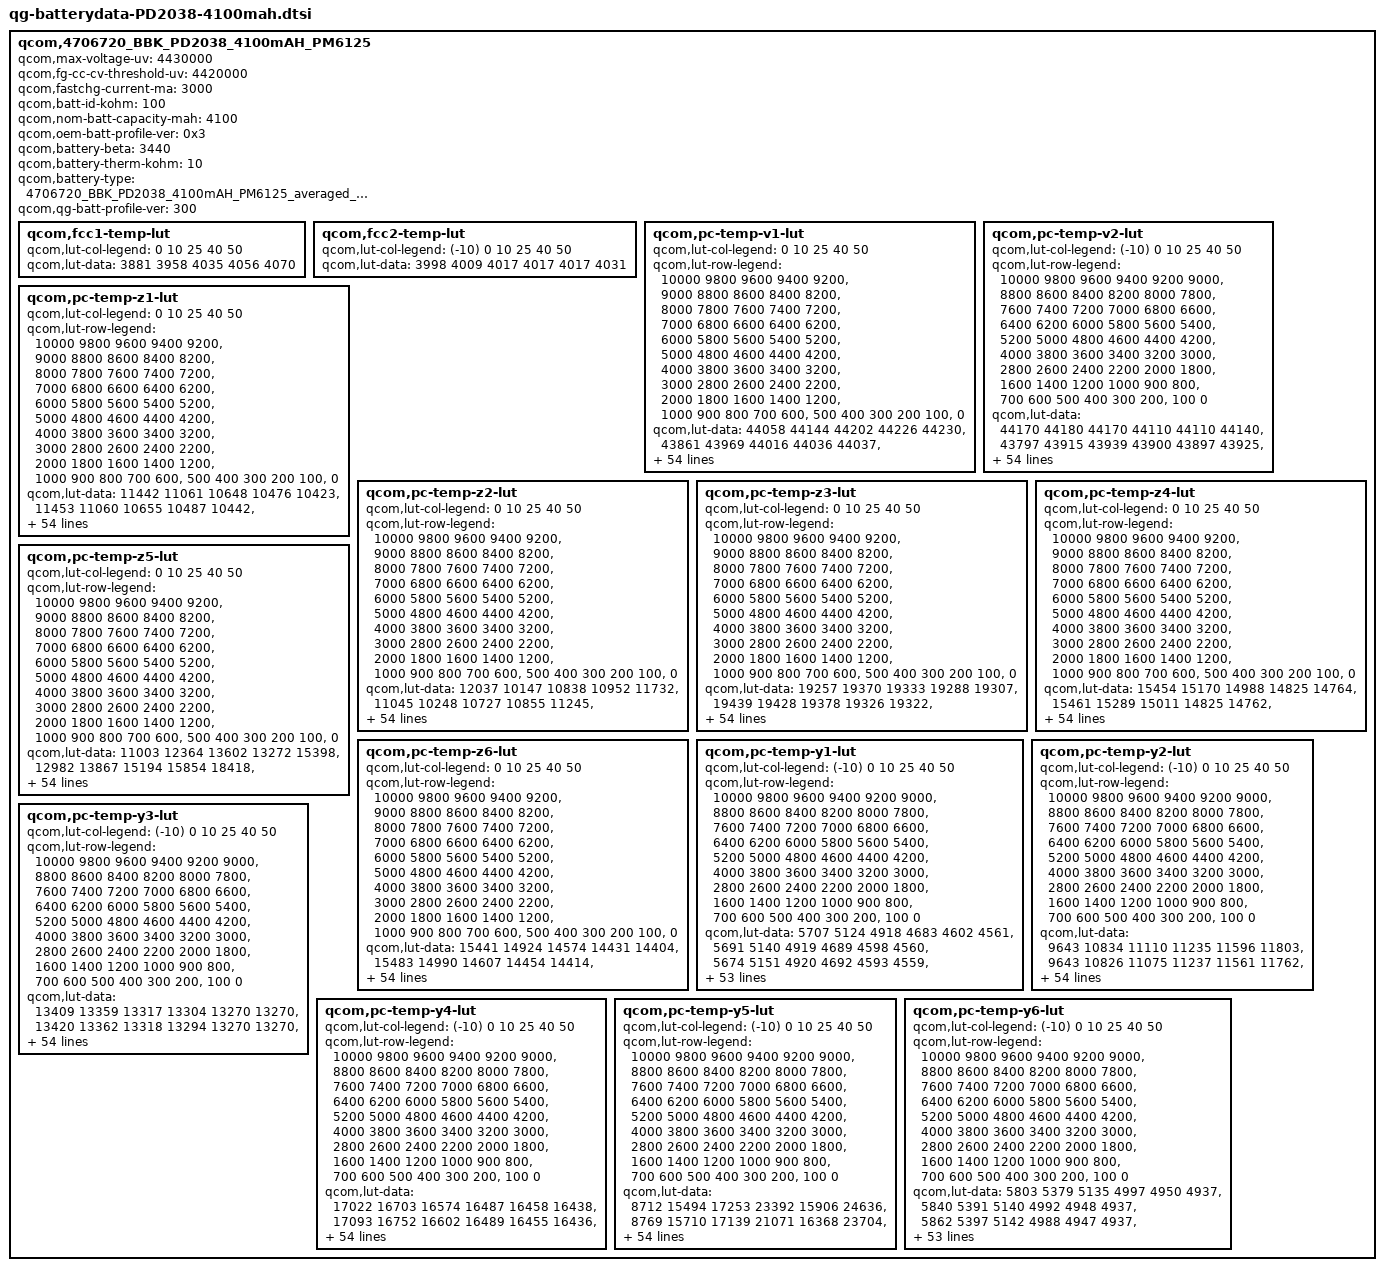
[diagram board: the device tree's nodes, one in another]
qcom,4706720_BBK_PD2038_4100mAH_PM6125 {
    /* 4706720_BBK_PD2038_4100mAH_PM6125_averaged_Master_Jul13th2020 */
    qcom,max-voltage-uv = <4430000>;
    qcom,fg-cc-cv-threshold-uv = <4420000>;
    qcom,fastchg-current-ma = <3000>;
    qcom,batt-id-kohm = <100>;
    qcom,nom-batt-capacity-mah = <4100>;/*min value*/
    qcom,oem-batt-profile-ver = <0x3>;
    qcom,battery-beta = <3440>;
    qcom,battery-therm-kohm = <10>;
    qcom,battery-type = "4706720_BBK_PD2038_4100mAH_PM6125_averaged_Master_Jul13th2020";
    qcom,qg-batt-profile-ver = <300>;

	qcom,fcc1-temp-lut {
		qcom,lut-col-legend = <0 10 25 40 50>;
		qcom,lut-data = <3881 3958 4035 4056 4070>;
	};

	qcom,fcc2-temp-lut {
		qcom,lut-col-legend = <(-10) 0 10 25 40 50>;
		qcom,lut-data = <3998 4009 4017 4017 4017 4031>;
	};

	qcom,pc-temp-v1-lut {
		qcom,lut-col-legend = <0 10 25 40 50>;
		qcom,lut-row-legend = <10000 9800 9600 9400 9200>,
			<9000 8800 8600 8400 8200>,
			<8000 7800 7600 7400 7200>,
			<7000 6800 6600 6400 6200>,
			<6000 5800 5600 5400 5200>,
			<5000 4800 4600 4400 4200>,
			<4000 3800 3600 3400 3200>,
			<3000 2800 2600 2400 2200>,
			<2000 1800 1600 1400 1200>,
			<1000 900 800 700 600>,
			<500 400 300 200 100>,
			<0>;
		qcom,lut-data = <44058 44144 44202 44226 44230>,
			<43861 43969 44016 44036 44037>,
			<43654 43771 43822 43841 43841>,
			<43436 43559 43622 43640 43642>,
			<43206 43339 43412 43434 43441>,
			<42971 43107 43188 43217 43229>,
			<42736 42872 42953 42990 43001>,
			<42499 42633 42714 42756 42767>,
			<42267 42393 42475 42519 42531>,
			<42035 42156 42234 42276 42291>,
			<41807 41923 41996 42038 42054>,
			<41589 41695 41760 41801 41818>,
			<41375 41471 41530 41570 41586>,
			<41171 41253 41306 41342 41359>,
			<40977 41044 41088 41120 41137>,
			<40789 40845 40878 40906 40921>,
			<40600 40653 40673 40699 40712>,
			<40412 40466 40476 40499 40509>,
			<40218 40285 40296 40314 40320>,
			<40004 40090 40118 40135 40140>,
			<39772 39849 39914 39939 39947>,
			<39563 39598 39679 39714 39724>,
			<39387 39397 39455 39492 39501>,
			<39231 39228 39263 39294 39303>,
			<39102 39083 39089 39111 39120>,
			<38992 38961 38943 38956 38962>,
			<38898 38854 38820 38827 38830>,
			<38813 38755 38711 38714 38713>,
			<38737 38662 38610 38607 38603>,
			<38667 38577 38517 38508 38501>,
			<38601 38504 38434 38417 38408>,
			<38538 38438 38358 38332 38323>,
			<38481 38378 38289 38255 38245>,
			<38428 38323 38231 38187 38174>,
			<38378 38273 38180 38128 38111>,
			<38333 38227 38129 38066 38042>,
			<38292 38187 38083 38002 37962>,
			<38235 38138 38032 37932 37876>,
			<38144 38056 37958 37852 37786>,
			<38028 37945 37860 37758 37693>,
			<37904 37825 37749 37653 37588>,
			<37764 37691 37626 37530 37462>,
			<37601 37540 37486 37391 37321>,
			<37418 37364 37315 37227 37158>,
			<37303 37212 37170 37095 37033>,
			<37218 37130 37092 37023 36968>,
			<37185 37106 37069 37007 36950>,
			<37157 37089 37049 36990 36935>,
			<37119 37059 37025 36966 36909>,
			<37011 36965 36930 36849 36739>,
			<36669 36616 36587 36497 36373>,
			<36182 36137 36120 36035 35898>,
			<35564 35523 35517 35441 35285>,
			<34723 34683 34697 34634 34449>,
			<33386 33352 33411 33394 33146>,
			<30000 30000 30000 30000 30000>;
	};

	qcom,pc-temp-v2-lut {
		qcom,lut-col-legend = <(-10) 0 10 25 40 50>;
		qcom,lut-row-legend = <10000 9800 9600 9400 9200 9000>,
			<8800 8600 8400 8200 8000 7800>,
			<7600 7400 7200 7000 6800 6600>,
			<6400 6200 6000 5800 5600 5400>,
			<5200 5000 4800 4600 4400 4200>,
			<4000 3800 3600 3400 3200 3000>,
			<2800 2600 2400 2200 2000 1800>,
			<1600 1400 1200 1000 900 800>,
			<700 600 500 400 300 200>,
			<100 0>;
		qcom,lut-data = <44170 44180 44170 44110 44110 44140>,
			<43797 43915 43939 43900 43897 43925>,
			<43470 43661 43712 43687 43683 43709>,
			<43198 43421 43491 43471 43468 43495>,
			<42979 43196 43277 43254 43254 43283>,
			<42764 42971 43059 43031 43036 43066>,
			<42521 42736 42827 42801 42806 42837>,
			<42270 42498 42588 42566 42570 42601>,
			<42030 42261 42352 42330 42334 42366>,
			<41804 42024 42115 42092 42096 42128>,
			<41585 41791 41881 41856 41861 41892>,
			<41373 41561 41651 41624 41630 41659>,
			<41168 41335 41425 41396 41404 41430>,
			<40966 41120 41203 41172 41181 41206>,
			<40775 40917 40985 40953 40963 40986>,
			<40573 40719 40771 40740 40751 40773>,
			<40315 40516 40564 40536 40549 40567>,
			<39994 40312 40362 40339 40353 40368>,
			<39700 40090 40153 40141 40161 40174>,
			<39462 39825 39931 39941 39974 39990>,
			<39246 39550 39701 39735 39782 39801>,
			<39038 39311 39465 39508 39557 39572>,
			<38836 39094 39217 39255 39294 39309>,
			<38659 38906 39006 39040 39071 39091>,
			<38515 38749 38848 38882 38915 38935>,
			<38393 38611 38713 38749 38784 38804>,
			<38292 38483 38588 38628 38663 38680>,
			<38211 38364 38472 38518 38552 38567>,
			<38139 38254 38365 38417 38450 38462>,
			<38072 38151 38265 38321 38354 38365>,
			<38012 38057 38172 38232 38265 38274>,
			<37954 37985 38086 38149 38184 38191>,
			<37901 37931 38006 38075 38113 38117>,
			<37847 37882 37933 38001 38039 38036>,
			<37788 37833 37870 37925 37950 37937>,
			<37724 37786 37814 37846 37851 37828>,
			<37655 37736 37755 37761 37750 37717>,
			<37578 37690 37695 37666 37643 37602>,
			<37495 37634 37628 37567 37538 37492>,
			<37398 37550 37543 37476 37443 37396>,
			<37287 37426 37438 37388 37354 37306>,
			<37166 37285 37319 37283 37249 37196>,
			<37029 37123 37171 37134 37105 37049>,
			<36895 36966 37030 37007 36979 36927>,
			<36792 36835 36914 36925 36891 36837>,
			<36700 36748 36847 36884 36851 36804>,
			<36654 36716 36819 36866 36836 36786>,
			<36596 36679 36786 36833 36808 36755>,
			<36493 36619 36723 36756 36746 36665>,
			<36262 36463 36565 36515 36540 36407>,
			<35860 36084 36175 36070 36120 35958>,
			<35289 35559 35615 35491 35580 35387>,
			<34507 34862 34913 34726 34868 34628>,
			<33360 33903 33905 33630 33865 33557>,
			<31486 32325 32298 32018 32384 32107>,
			<29018 29007 29005 29349 30157 29005>;
	};

	qcom,pc-temp-z1-lut {
		qcom,lut-col-legend = <0 10 25 40 50>;
		qcom,lut-row-legend = <10000 9800 9600 9400 9200>,
			<9000 8800 8600 8400 8200>,
			<8000 7800 7600 7400 7200>,
			<7000 6800 6600 6400 6200>,
			<6000 5800 5600 5400 5200>,
			<5000 4800 4600 4400 4200>,
			<4000 3800 3600 3400 3200>,
			<3000 2800 2600 2400 2200>,
			<2000 1800 1600 1400 1200>,
			<1000 900 800 700 600>,
			<500 400 300 200 100>,
			<0>;
		qcom,lut-data = <11442 11061 10648 10476 10423>,
			<11453 11060 10655 10487 10442>,
			<11458 11063 10656 10492 10453>,
			<11458 11067 10653 10491 10452>,
			<11451 11066 10650 10487 10450>,
			<11444 11061 10646 10485 10448>,
			<11439 11058 10643 10483 10446>,
			<11435 11060 10641 10481 10444>,
			<11432 11064 10640 10478 10443>,
			<11430 11064 10639 10475 10441>,
			<11429 11062 10636 10474 10441>,
			<11431 11060 10632 10474 10442>,
			<11440 11059 10629 10474 10444>,
			<11446 11058 10629 10474 10444>,
			<11444 11057 10630 10473 10444>,
			<11440 11047 10630 10473 10444>,
			<11434 11037 10633 10476 10445>,
			<11420 11034 10635 10479 10446>,
			<11408 11033 10634 10478 10447>,
			<11408 11033 10631 10476 10448>,
			<11411 11042 10631 10476 10449>,
			<11413 11055 10633 10477 10451>,
			<11414 11057 10636 10480 10453>,
			<11415 11049 10639 10482 10454>,
			<11418 11044 10643 10486 10455>,
			<11426 11049 10647 10490 10456>,
			<11435 11058 10654 10493 10459>,
			<11438 11061 10659 10496 10461>,
			<11440 11055 10662 10498 10464>,
			<11440 11049 10664 10499 10465>,
			<11429 11049 10666 10501 10467>,
			<11415 11050 10666 10502 10469>,
			<11414 11050 10667 10504 10471>,
			<11424 11050 10669 10506 10473>,
			<11433 11050 10673 10509 10475>,
			<11436 11051 10678 10512 10477>,
			<11438 11054 10683 10514 10479>,
			<11439 11059 10686 10516 10480>,
			<11441 11066 10686 10518 10483>,
			<11443 11076 10686 10520 10485>,
			<11439 11077 10686 10522 10487>,
			<11423 11069 10686 10524 10488>,
			<11419 11066 10687 10526 10489>,
			<11423 11069 10694 10526 10492>,
			<11422 11070 10694 10525 10491>,
			<11434 11071 10700 10530 10493>,
			<11448 11073 10702 10525 10491>,
			<11436 11086 10694 10526 10492>,
			<11430 11087 10695 10528 10493>,
			<11445 11089 10698 10533 10497>,
			<11431 11095 10703 10533 10503>,
			<11440 11091 10716 10540 10503>,
			<11452 11117 10725 10544 10512>,
			<11466 11111 10730 10553 10517>,
			<11466 11111 10730 10553 10517>,
			<11466 11111 10730 10553 10517>;
	};

	qcom,pc-temp-z2-lut {
		qcom,lut-col-legend = <0 10 25 40 50>;
		qcom,lut-row-legend = <10000 9800 9600 9400 9200>,
			<9000 8800 8600 8400 8200>,
			<8000 7800 7600 7400 7200>,
			<7000 6800 6600 6400 6200>,
			<6000 5800 5600 5400 5200>,
			<5000 4800 4600 4400 4200>,
			<4000 3800 3600 3400 3200>,
			<3000 2800 2600 2400 2200>,
			<2000 1800 1600 1400 1200>,
			<1000 900 800 700 600>,
			<500 400 300 200 100>,
			<0>;
		qcom,lut-data = <12037 10147 10838 10952 11732>,
			<11045 10248 10727 10855 11245>,
			<10384 10336 10693 10809 10964>,
			<10275 10399 10707 10808 10928>,
			<10263 10415 10722 10808 10913>,
			<10259 10421 10720 10806 10911>,
			<10264 10423 10710 10797 10923>,
			<10275 10422 10698 10791 10942>,
			<10278 10419 10683 10799 10957>,
			<10277 10417 10670 10817 10972>,
			<10276 10414 10666 10833 10988>,
			<10272 10412 10664 10848 11006>,
			<10264 10408 10661 10864 11019>,
			<10260 10405 10637 10884 11000>,
			<10262 10401 10607 10908 10949>,
			<10266 10397 10606 10937 10935>,
			<10271 10392 10621 10983 11040>,
			<10279 10388 10631 11014 11148>,
			<10286 10383 10623 11009 11144>,
			<10277 10382 10608 10991 11105>,
			<10247 10390 10595 10960 11065>,
			<10230 10403 10581 10866 11029>,
			<10242 10406 10574 10789 10990>,
			<10261 10406 10612 10793 10935>,
			<10265 10406 10682 10812 10865>,
			<10259 10396 10700 10818 10840>,
			<10252 10378 10693 10790 10873>,
			<10250 10372 10684 10761 10919>,
			<10248 10382 10669 10771 10943>,
			<10246 10395 10651 10805 10961>,
			<10226 10403 10649 10828 10967>,
			<10202 10409 10691 10835 10956>,
			<10204 10412 10731 10841 10943>,
			<10243 10407 10735 10859 10967>,
			<10278 10400 10735 10894 11068>,
			<10286 10396 10739 10933 11147>,
			<10290 10393 10778 10985 11179>,
			<10296 10392 10834 11030 11205>,
			<10306 10426 10880 11039 11246>,
			<10314 10487 10926 11043 11304>,
			<10315 10504 10941 11044 11331>,
			<10309 10491 10877 11040 11283>,
			<10298 10484 10833 11031 11220>,
			<10284 10481 10847 11009 11181>,
			<10768 10504 10814 11036 11233>,
			<15094 10479 10899 11076 11158>,
			<14915 10478 10867 11113 11118>,
			<14921 10458 10785 11116 11159>,
			<14655 10450 10805 11094 11275>,
			<14225 10507 10896 10932 10895>,
			<14290 10506 10836 10685 10787>,
			<15438 10540 10807 10695 10696>,
			<12299 10555 10667 10601 10677>,
			<11020 10448 10545 10593 10711>,
			<11020 10448 10545 10593 10711>,
			<11020 10448 10545 10593 10711>;
	};

	qcom,pc-temp-z3-lut {
		qcom,lut-col-legend = <0 10 25 40 50>;
		qcom,lut-row-legend = <10000 9800 9600 9400 9200>,
			<9000 8800 8600 8400 8200>,
			<8000 7800 7600 7400 7200>,
			<7000 6800 6600 6400 6200>,
			<6000 5800 5600 5400 5200>,
			<5000 4800 4600 4400 4200>,
			<4000 3800 3600 3400 3200>,
			<3000 2800 2600 2400 2200>,
			<2000 1800 1600 1400 1200>,
			<1000 900 800 700 600>,
			<500 400 300 200 100>,
			<0>;
		qcom,lut-data = <19257 19370 19333 19288 19307>,
			<19439 19428 19378 19326 19322>,
			<19569 19484 19392 19344 19329>,
			<19622 19524 19392 19344 19326>,
			<19653 19527 19392 19343 19318>,
			<19666 19524 19391 19340 19316>,
			<19660 19520 19389 19333 19317>,
			<19648 19517 19387 19328 19319>,
			<19641 19513 19382 19329 19318>,
			<19640 19509 19376 19330 19316>,
			<19639 19505 19373 19330 19315>,
			<19636 19501 19372 19328 19314>,
			<19628 19499 19369 19326 19314>,
			<19621 19497 19360 19324 19310>,
			<19618 19495 19350 19321 19304>,
			<19615 19493 19349 19318 19302>,
			<19615 19491 19350 19313 19303>,
			<19618 19491 19350 19310 19304>,
			<19624 19492 19351 19310 19304>,
			<19633 19493 19352 19310 19303>,
			<19647 19495 19355 19311 19303>,
			<19655 19501 19361 19315 19310>,
			<19653 19510 19370 19321 19318>,
			<19650 19530 19384 19326 19321>,
			<19650 19544 19400 19330 19322>,
			<19654 19541 19403 19332 19322>,
			<19658 19532 19403 19331 19322>,
			<19653 19525 19401 19331 19321>,
			<19638 19520 19398 19330 19321>,
			<19625 19514 19393 19328 19320>,
			<19616 19507 19389 19326 19318>,
			<19608 19499 19386 19325 19312>,
			<19603 19492 19383 19324 19306>,
			<19598 19487 19379 19323 19303>,
			<19595 19483 19376 19321 19301>,
			<19594 19481 19373 19319 19300>,
			<19593 19481 19371 19317 19302>,
			<19592 19480 19368 19315 19305>,
			<19584 19475 19366 19314 19305>,
			<19573 19465 19362 19315 19303>,
			<19568 19460 19359 19316 19302>,
			<19566 19459 19356 19321 19304>,
			<19563 19456 19354 19325 19307>,
			<19554 19445 19354 19324 19310>,
			<19286 19436 19352 19322 19309>,
			<19257 19431 19342 19319 19301>,
			<19257 19427 19343 19307 19303>,
			<19257 19414 19342 19309 19299>,
			<19257 19412 19337 19309 19298>,
			<19257 19381 19345 19321 19319>,
			<19257 19364 19331 19329 19318>,
			<19257 19369 19334 19332 19319>,
			<19257 19333 19344 19329 19322>,
			<19258 19353 19345 19334 19323>,
			<19258 19353 19345 19334 19323>,
			<19258 19353 19345 19334 19323>;
	};

	qcom,pc-temp-z4-lut {
		qcom,lut-col-legend = <0 10 25 40 50>;
		qcom,lut-row-legend = <10000 9800 9600 9400 9200>,
			<9000 8800 8600 8400 8200>,
			<8000 7800 7600 7400 7200>,
			<7000 6800 6600 6400 6200>,
			<6000 5800 5600 5400 5200>,
			<5000 4800 4600 4400 4200>,
			<4000 3800 3600 3400 3200>,
			<3000 2800 2600 2400 2200>,
			<2000 1800 1600 1400 1200>,
			<1000 900 800 700 600>,
			<500 400 300 200 100>,
			<0>;
		qcom,lut-data = <15454 15170 14988 14825 14764>,
			<15461 15289 15011 14825 14762>,
			<15462 15247 15011 14825 14759>,
			<15438 15179 14960 14813 14755>,
			<15307 15118 14899 14790 14749>,
			<15182 15053 14876 14777 14743>,
			<15131 15007 14863 14769 14736>,
			<15095 14984 14850 14762 14728>,
			<15071 14967 14838 14754 14722>,
			<15054 14951 14826 14745 14716>,
			<15040 14935 14813 14737 14710>,
			<15030 14921 14801 14729 14703>,
			<15021 14908 14790 14722 14697>,
			<15012 14896 14783 14714 14692>,
			<14999 14889 14776 14707 14689>,
			<14986 14885 14767 14700 14683>,
			<14986 14882 14756 14693 14673>,
			<15019 14882 14747 14686 14663>,
			<15071 14883 14742 14681 14659>,
			<15128 14885 14739 14677 14656>,
			<15200 14982 14752 14680 14656>,
			<15241 15121 14837 14718 14679>,
			<15251 15144 14898 14760 14709>,
			<15257 15104 14895 14774 14724>,
			<15253 15061 14886 14782 14734>,
			<15212 15033 14876 14784 14737>,
			<15166 15010 14857 14775 14732>,
			<15145 14996 14840 14763 14725>,
			<15130 14989 14828 14752 14717>,
			<15124 14984 14820 14742 14709>,
			<15123 14978 14813 14732 14702>,
			<15122 14974 14807 14723 14696>,
			<15120 14971 14803 14715 14691>,
			<15115 14969 14800 14710 14687>,
			<15109 14968 14798 14707 14682>,
			<15102 14965 14798 14706 14680>,
			<15094 14960 14811 14725 14694>,
			<15086 14955 14824 14748 14711>,
			<15077 14951 14825 14749 14712>,
			<15066 14947 14824 14741 14704>,
			<15044 14937 14822 14731 14696>,
			<15001 14904 14804 14717 14688>,
			<14962 14873 14785 14709 14683>,
			<14931 14851 14778 14707 14681>,
			<15065 14816 14770 14707 14682>,
			<15056 14775 14753 14704 14683>,
			<15042 14754 14728 14695 14669>,
			<15026 14736 14704 14673 14655>,
			<15022 14729 14693 14662 14647>,
			<15026 14768 14700 14659 14642>,
			<15037 14796 14715 14654 14641>,
			<15037 14785 14708 14649 14642>,
			<15037 14822 14697 14652 14640>,
			<15042 14801 14696 14648 14641>,
			<15042 14801 14696 14648 14641>,
			<15042 14801 14696 14648 14641>;
	};

	qcom,pc-temp-z5-lut {
		qcom,lut-col-legend = <0 10 25 40 50>;
		qcom,lut-row-legend = <10000 9800 9600 9400 9200>,
			<9000 8800 8600 8400 8200>,
			<8000 7800 7600 7400 7200>,
			<7000 6800 6600 6400 6200>,
			<6000 5800 5600 5400 5200>,
			<5000 4800 4600 4400 4200>,
			<4000 3800 3600 3400 3200>,
			<3000 2800 2600 2400 2200>,
			<2000 1800 1600 1400 1200>,
			<1000 900 800 700 600>,
			<500 400 300 200 100>,
			<0>;
		qcom,lut-data = <11003 12364 13602 13272 15398>,
			<12982 13867 15194 15854 18418>,
			<14697 15269 16092 17413 19950>,
			<16129 16452 16549 18058 19540>,
			<17422 17214 16838 18446 18534>,
			<18332 17789 17017 18392 18241>,
			<18780 18145 17150 17711 18693>,
			<19085 18318 17189 17224 19177>,
			<19421 18437 17067 17530 19323>,
			<19899 18558 16922 18108 19406>,
			<20267 18667 16968 18340 19509>,
			<20302 18798 17190 18424 19675>,
			<20272 19016 17303 18461 19794>,
			<20254 19323 16796 18458 19395>,
			<20410 19647 16117 18446 18337>,
			<20687 20066 16074 18372 17966>,
			<20761 20385 16434 17870 18723>,
			<20623 20377 16892 17444 19683>,
			<20484 20202 17527 17707 20186>,
			<20807 19952 18157 18312 20567>,
			<21899 19416 18017 18370 20611>,
			<22513 18785 16489 16725 18850>,
			<21364 18528 15387 15192 16811>,
			<19599 18402 15549 15121 16360>,
			<19297 18345 15976 15135 16168>,
			<20453 18650 16479 15176 16124>,
			<21602 19441 17184 15541 16499>,
			<21907 20273 17934 16078 17116>,
			<22078 21317 18556 16545 17737>,
			<22153 22173 19152 17035 18454>,
			<22172 22446 19894 17630 18739>,
			<22187 22595 20934 18422 18457>,
			<22228 22687 21947 19323 18113>,
			<22344 22739 22743 20352 18321>,
			<22497 22784 23433 21522 19251>,
			<22706 22890 23624 21939 19736>,
			<22957 23115 23184 20461 19450>,
			<23043 23255 22437 18674 18982>,
			<22913 22869 21483 18426 18638>,
			<22715 22127 20183 18402 18321>,
			<22586 21807 19414 18414 18191>,
			<22492 21741 19183 19667 18831>,
			<22310 21469 18943 20638 19441>,
			<21785 19975 18486 19866 19530>,
			<12696 20505 18198 18851 19092>,
			<11295 20788 17505 18648 17427>,
			<11222 20915 19092 17510 19498>,
			<11119 19131 21063 20205 21396>,
			<11104 19090 21431 22638 22854>,
			<11116 15310 18895 20722 29444>,
			<11109 13832 15254 23449 28009>,
			<11073 13877 15358 24963 29176>,
			<11018 12472 16171 22772 31523>,
			<10956 12950 15863 24829 31491>,
			<10956 12950 15863 24829 31491>,
			<10956 12950 15863 24829 31491>;
	};

	qcom,pc-temp-z6-lut {
		qcom,lut-col-legend = <0 10 25 40 50>;
		qcom,lut-row-legend = <10000 9800 9600 9400 9200>,
			<9000 8800 8600 8400 8200>,
			<8000 7800 7600 7400 7200>,
			<7000 6800 6600 6400 6200>,
			<6000 5800 5600 5400 5200>,
			<5000 4800 4600 4400 4200>,
			<4000 3800 3600 3400 3200>,
			<3000 2800 2600 2400 2200>,
			<2000 1800 1600 1400 1200>,
			<1000 900 800 700 600>,
			<500 400 300 200 100>,
			<0>;
		qcom,lut-data = <15441 14924 14574 14431 14404>,
			<15483 14990 14607 14454 14414>,
			<15493 14979 14615 14464 14418>,
			<15478 14959 14591 14459 14416>,
			<15391 14932 14562 14447 14409>,
			<15304 14891 14549 14439 14404>,
			<15258 14858 14541 14431 14400>,
			<15222 14839 14533 14425 14398>,
			<15197 14824 14524 14421 14394>,
			<15179 14810 14514 14418 14391>,
			<15166 14797 14507 14414 14388>,
			<15152 14786 14500 14409 14385>,
			<15139 14776 14493 14405 14381>,
			<15127 14767 14485 14400 14377>,
			<15115 14761 14477 14396 14373>,
			<15104 14757 14471 14391 14369>,
			<15102 14753 14467 14386 14365>,
			<15116 14753 14464 14381 14362>,
			<15137 14753 14463 14379 14360>,
			<15166 14754 14463 14377 14358>,
			<15207 14800 14469 14379 14358>,
			<15231 14865 14509 14399 14373>,
			<15237 14878 14542 14421 14392>,
			<15241 14873 14550 14431 14400>,
			<15240 14865 14554 14437 14405>,
			<15227 14855 14554 14439 14407>,
			<15211 14841 14547 14435 14405>,
			<15199 14833 14539 14429 14401>,
			<15189 14829 14533 14424 14398>,
			<15182 14826 14527 14419 14394>,
			<15179 14822 14523 14414 14390>,
			<15177 14818 14520 14410 14384>,
			<15177 14816 14517 14406 14379>,
			<15177 14815 14515 14403 14376>,
			<15178 14815 14513 14401 14373>,
			<15180 14815 14512 14401 14372>,
			<15185 14817 14518 14408 14379>,
			<15186 14819 14523 14417 14388>,
			<15186 14818 14523 14417 14389>,
			<15186 14817 14522 14414 14385>,
			<15184 14815 14520 14411 14381>,
			<15175 14806 14512 14408 14379>,
			<15172 14797 14504 14407 14378>,
			<15172 14790 14502 14406 14380>,
			<15119 14778 14498 14405 14380>,
			<15108 14764 14487 14402 14376>,
			<15110 14755 14478 14392 14371>,
			<15110 14744 14467 14384 14363>,
			<15116 14744 14461 14379 14359>,
			<15130 14752 14470 14385 14369>,
			<15147 14762 14471 14388 14369>,
			<15161 14767 14472 14389 14372>,
			<15179 14774 14475 14390 14374>,
			<15207 14788 14479 14394 14377>,
			<15207 14788 14479 14394 14377>,
			<15207 14788 14479 14394 14377>;
	};

	qcom,pc-temp-y1-lut {
		qcom,lut-col-legend = <(-10) 0 10 25 40 50>;
		qcom,lut-row-legend = <10000 9800 9600 9400 9200 9000>,
			<8800 8600 8400 8200 8000 7800>,
			<7600 7400 7200 7000 6800 6600>,
			<6400 6200 6000 5800 5600 5400>,
			<5200 5000 4800 4600 4400 4200>,
			<4000 3800 3600 3400 3200 3000>,
			<2800 2600 2400 2200 2000 1800>,
			<1600 1400 1200 1000 900 800>,
			<700 600 500 400 300 200>,
			<100 0>;
		qcom,lut-data = <5707 5124 4918 4683 4602 4561>,
			<5691 5140 4919 4689 4598 4560>,
			<5674 5151 4920 4692 4593 4559>,
			<5658 5156 4920 4692 4589 4558>,
			<5644 5158 4920 4690 4585 4558>,
			<5634 5159 4920 4687 4582 4557>,
			<5626 5154 4919 4682 4581 4557>,
			<5621 5143 4916 4675 4580 4557>,
			<5620 5136 4914 4672 4578 4557>,
			<5620 5134 4911 4672 4573 4557>,
			<5621 5131 4909 4672 4569 4556>,
			<5620 5128 4907 4671 4570 4556>,
			<5616 5125 4904 4669 4572 4556>,
			<5615 5123 4902 4667 4574 4556>,
			<5615 5121 4901 4665 4575 4555>,
			<5615 5119 4900 4664 4576 4555>,
			<5615 5119 4899 4663 4576 4555>,
			<5614 5119 4898 4663 4576 4556>,
			<5614 5119 4898 4663 4576 4556>,
			<5611 5117 4898 4665 4577 4558>,
			<5609 5115 4899 4666 4578 4559>,
			<5611 5116 4900 4667 4579 4559>,
			<5623 5122 4903 4667 4579 4559>,
			<5631 5126 4905 4667 4579 4558>,
			<5623 5121 4902 4668 4580 4559>,
			<5607 5112 4898 4669 4581 4560>,
			<5604 5110 4898 4670 4582 4561>,
			<5614 5112 4903 4672 4582 4563>,
			<5623 5114 4908 4674 4582 4565>,
			<5616 5118 4909 4677 4584 4565>,
			<5597 5125 4911 4681 4586 4565>,
			<5587 5127 4911 4683 4588 4566>,
			<5584 5127 4909 4685 4589 4568>,
			<5583 5126 4908 4686 4590 4570>,
			<5581 5123 4908 4687 4592 4570>,
			<5579 5115 4909 4688 4594 4571>,
			<5577 5110 4910 4689 4596 4572>,
			<5576 5109 4910 4692 4597 4574>,
			<5575 5108 4910 4694 4597 4576>,
			<5574 5108 4913 4694 4599 4577>,
			<5572 5108 4919 4694 4600 4578>,
			<5571 5109 4923 4695 4601 4579>,
			<5572 5115 4924 4696 4603 4581>,
			<5573 5121 4924 4699 4603 4582>,
			<5578 5124 4919 4702 4602 4582>,
			<5595 5116 4919 4701 4605 4583>,
			<5612 5108 4920 4700 4607 4582>,
			<5619 5109 4930 4704 4607 4581>,
			<5625 5112 4931 4702 4605 4583>,
			<5611 5126 4923 4706 4607 4586>,
			<5629 5130 4934 4710 4609 4588>,
			<5668 5123 4930 4713 4611 4591>,
			<5684 5132 4948 4714 4619 4595>,
			<5767 5178 4958 4730 4624 4601>,
			<5767 5178 4958 4730 4624 4601>,
			<5767 5178 4958 4730 4624 4601>;
	};

	qcom,pc-temp-y2-lut {
		qcom,lut-col-legend = <(-10) 0 10 25 40 50>;
		qcom,lut-row-legend = <10000 9800 9600 9400 9200 9000>,
			<8800 8600 8400 8200 8000 7800>,
			<7600 7400 7200 7000 6800 6600>,
			<6400 6200 6000 5800 5600 5400>,
			<5200 5000 4800 4600 4400 4200>,
			<4000 3800 3600 3400 3200 3000>,
			<2800 2600 2400 2200 2000 1800>,
			<1600 1400 1200 1000 900 800>,
			<700 600 500 400 300 200>,
			<100 0>;
		qcom,lut-data = <9643 10834 11110 11235 11596 11803>,
			<9643 10826 11075 11237 11561 11762>,
			<9643 10818 11040 11238 11524 11723>,
			<9936 10810 11006 11238 11488 11686>,
			<10329 10800 10978 11237 11457 11652>,
			<10530 10790 10956 11236 11435 11619>,
			<10550 10778 10939 11187 11425 11593>,
			<10559 10765 10927 11095 11418 11567>,
			<10564 10761 10924 11070 11400 11524>,
			<10565 10765 10929 11100 11344 11432>,
			<10568 10771 10937 11126 11298 11366>,
			<10599 10779 10945 11128 11304 11412>,
			<10677 10789 10955 11128 11329 11518>,
			<10709 10807 10967 11128 11354 11548>,
			<10662 10866 10982 11138 11382 11467>,
			<10608 10923 11003 11157 11403 11389>,
			<10612 10925 11047 11190 11382 11407>,
			<10653 10915 11120 11252 11312 11475>,
			<10677 10908 11152 11323 11282 11519>,
			<10680 10907 11130 11427 11394 11534>,
			<10681 10907 11101 11517 11557 11548>,
			<10599 10911 11095 11515 11639 11610>,
			<10148 10929 11093 11460 11695 11750>,
			<9803 10947 11093 11428 11725 11819>,
			<9763 10957 11110 11462 11735 11822>,
			<9742 10965 11140 11513 11741 11824>,
			<9726 10976 11164 11518 11751 11847>,
			<9712 10988 11188 11491 11764 11929>,
			<9701 11009 11200 11472 11783 11992>,
			<9695 11151 11198 11493 11858 12009>,
			<9690 11399 11193 11540 11965 12022>,
			<9686 11440 11181 11576 11980 12053>,
			<9680 11060 11139 11609 11882 12124>,
			<9675 10641 11102 11628 11799 12179>,
			<9672 10477 11092 11597 11843 12199>,
			<9669 10367 11086 11527 11944 12212>,
			<9667 10341 11085 11506 11973 12201>,
			<9665 10475 11092 11555 11897 12100>,
			<9663 10623 11099 11605 11822 12020>,
			<9662 10541 11081 11612 11818 12041>,
			<9660 10188 11020 11614 11819 12088>,
			<9659 9914 10951 11615 11820 12086>,
			<9658 9782 10878 11616 11818 11926>,
			<9658 9710 10792 11611 11811 11838>,
			<9657 9687 10686 11436 11737 11820>,
			<9656 9678 10574 11429 11686 11822>,
			<9656 9675 10551 11445 11655 11676>,
			<9655 9671 10569 11441 11584 11486>,
			<9654 9667 10507 11375 11546 11451>,
			<9654 9664 10454 11202 11362 11403>,
			<9653 9660 10321 11192 11301 11319>,
			<9651 9658 9934 11072 11178 11269>,
			<9649 9655 9814 11001 11188 11263>,
			<9654 9651 9708 10901 11138 11215>,
			<9654 9651 9708 10901 11138 11215>,
			<9654 9651 9708 10901 11138 11215>;
	};

	qcom,pc-temp-y3-lut {
		qcom,lut-col-legend = <(-10) 0 10 25 40 50>;
		qcom,lut-row-legend = <10000 9800 9600 9400 9200 9000>,
			<8800 8600 8400 8200 8000 7800>,
			<7600 7400 7200 7000 6800 6600>,
			<6400 6200 6000 5800 5600 5400>,
			<5200 5000 4800 4600 4400 4200>,
			<4000 3800 3600 3400 3200 3000>,
			<2800 2600 2400 2200 2000 1800>,
			<1600 1400 1200 1000 900 800>,
			<700 600 500 400 300 200>,
			<100 0>;
		qcom,lut-data = <13409 13359 13317 13304 13270 13270>,
			<13420 13362 13318 13294 13270 13270>,
			<13438 13365 13319 13288 13271 13270>,
			<13458 13368 13321 13283 13271 13270>,
			<13474 13370 13322 13280 13272 13270>,
			<13483 13372 13323 13279 13272 13271>,
			<13485 13373 13323 13281 13273 13271>,
			<13486 13374 13323 13285 13274 13272>,
			<13487 13375 13323 13286 13275 13272>,
			<13490 13377 13324 13286 13275 13273>,
			<13492 13379 13326 13286 13275 13273>,
			<13487 13379 13328 13287 13275 13274>,
			<13473 13379 13330 13287 13275 13274>,
			<13459 13379 13331 13287 13275 13274>,
			<13450 13378 13331 13287 13275 13273>,
			<13441 13375 13330 13287 13275 13273>,
			<13433 13371 13328 13287 13275 13272>,
			<13425 13365 13326 13290 13277 13271>,
			<13417 13358 13324 13293 13279 13271>,
			<13411 13351 13321 13294 13282 13274>,
			<13405 13344 13318 13295 13284 13278>,
			<13394 13339 13314 13294 13283 13277>,
			<13377 13334 13309 13287 13275 13272>,
			<13356 13331 13307 13283 13270 13270>,
			<13325 13329 13306 13280 13270 13270>,
			<13292 13328 13306 13279 13270 13270>,
			<13284 13327 13306 13279 13270 13269>,
			<13293 13324 13306 13280 13270 13269>,
			<13305 13321 13305 13281 13270 13268>,
			<13313 13301 13305 13280 13270 13269>,
			<13320 13269 13304 13280 13270 13269>,
			<13332 13259 13303 13280 13270 13269>,
			<13360 13259 13301 13280 13271 13268>,
			<13394 13259 13300 13281 13272 13267>,
			<13423 13260 13300 13281 13271 13267>,
			<13450 13260 13301 13280 13270 13267>,
			<13483 13262 13301 13279 13270 13267>,
			<13525 13295 13303 13279 13270 13267>,
			<13577 13332 13304 13278 13270 13267>,
			<13637 13339 13304 13277 13270 13267>,
			<13709 13341 13304 13277 13271 13268>,
			<13793 13343 13303 13276 13271 13268>,
			<13887 13352 13308 13275 13271 13269>,
			<14004 13367 13314 13275 13270 13269>,
			<14164 13397 13321 13277 13271 13269>,
			<14368 13442 13329 13281 13272 13270>,
			<14488 13470 13332 13283 13273 13272>,
			<14601 13492 13335 13285 13274 13273>,
			<14780 13558 13345 13287 13276 13274>,
			<15034 13635 13358 13288 13278 13274>,
			<15423 13727 13364 13291 13278 13274>,
			<16613 13942 13376 13291 13278 13273>,
			<19581 14338 13427 13294 13277 13273>,
			<25299 15696 13549 13302 13278 13275>,
			<25299 15696 13549 13302 13278 13275>,
			<25299 15696 13549 13302 13278 13275>;
	};

	qcom,pc-temp-y4-lut {
		qcom,lut-col-legend = <(-10) 0 10 25 40 50>;
		qcom,lut-row-legend = <10000 9800 9600 9400 9200 9000>,
			<8800 8600 8400 8200 8000 7800>,
			<7600 7400 7200 7000 6800 6600>,
			<6400 6200 6000 5800 5600 5400>,
			<5200 5000 4800 4600 4400 4200>,
			<4000 3800 3600 3400 3200 3000>,
			<2800 2600 2400 2200 2000 1800>,
			<1600 1400 1200 1000 900 800>,
			<700 600 500 400 300 200>,
			<100 0>;
		qcom,lut-data = <17022 16703 16574 16487 16458 16438>,
			<17093 16752 16602 16489 16455 16436>,
			<17152 16803 16624 16491 16452 16436>,
			<17198 16850 16638 16494 16449 16435>,
			<17227 16884 16646 16496 16448 16435>,
			<17239 16900 16649 16497 16447 16435>,
			<17226 16894 16644 16497 16447 16435>,
			<17199 16880 16633 16497 16449 16436>,
			<17191 16867 16628 16498 16450 16437>,
			<17203 16854 16627 16503 16451 16438>,
			<17225 16845 16626 16509 16454 16441>,
			<17275 16848 16629 16516 16458 16444>,
			<17372 16860 16638 16524 16466 16448>,
			<17454 16880 16649 16533 16474 16453>,
			<17524 16941 16666 16544 16481 16459>,
			<17572 17016 16690 16557 16490 16467>,
			<17513 17068 16735 16572 16498 16475>,
			<17260 17113 16807 16591 16507 16484>,
			<17055 17129 16837 16611 16519 16494>,
			<16960 17032 16827 16637 16542 16510>,
			<16892 16876 16805 16658 16563 16523>,
			<16851 16776 16754 16639 16552 16512>,
			<16820 16698 16637 16552 16498 16471>,
			<16805 16648 16564 16495 16464 16448>,
			<16813 16625 16550 16487 16459 16445>,
			<16828 16609 16542 16483 16457 16444>,
			<16831 16595 16541 16483 16457 16445>,
			<16820 16582 16541 16489 16460 16448>,
			<16811 16574 16541 16497 16464 16452>,
			<16812 16593 16542 16505 16469 16456>,
			<16817 16636 16545 16516 16477 16462>,
			<16818 16660 16547 16526 16486 16469>,
			<16813 16669 16550 16537 16498 16480>,
			<16807 16678 16552 16544 16507 16486>,
			<16809 16697 16550 16542 16501 16477>,
			<16820 16723 16546 16534 16485 16461>,
			<16830 16732 16543 16522 16473 16455>,
			<16837 16711 16541 16495 16465 16453>,
			<16844 16688 16539 16472 16460 16451>,
			<16852 16686 16542 16471 16457 16450>,
			<16860 16687 16552 16474 16454 16448>,
			<16866 16689 16566 16477 16452 16446>,
			<16868 16704 16585 16480 16450 16440>,
			<16869 16725 16609 16482 16449 16439>,
			<16902 16747 16633 16483 16449 16439>,
			<16993 16794 16687 16503 16458 16444>,
			<17065 16829 16704 16516 16462 16445>,
			<17086 16851 16706 16518 16462 16448>,
			<17139 16911 16754 16522 16460 16444>,
			<17179 16958 16779 16502 16443 16435>,
			<17204 16966 16773 16503 16443 16438>,
			<17565 17035 16818 16524 16454 16451>,
			<19520 17214 16922 16567 16470 16468>,
			<32934 18176 17087 16687 16519 16576>,
			<32934 18176 17087 16687 16519 16576>,
			<32934 18176 17087 16687 16519 16576>;
	};

	qcom,pc-temp-y5-lut {
		qcom,lut-col-legend = <(-10) 0 10 25 40 50>;
		qcom,lut-row-legend = <10000 9800 9600 9400 9200 9000>,
			<8800 8600 8400 8200 8000 7800>,
			<7600 7400 7200 7000 6800 6600>,
			<6400 6200 6000 5800 5600 5400>,
			<5200 5000 4800 4600 4400 4200>,
			<4000 3800 3600 3400 3200 3000>,
			<2800 2600 2400 2200 2000 1800>,
			<1600 1400 1200 1000 900 800>,
			<700 600 500 400 300 200>,
			<100 0>;
		qcom,lut-data = <8712 15494 17253 23392 15906 24636>,
			<8769 15710 17139 21071 16368 23704>,
			<10566 15871 16985 18510 16689 22501>,
			<12702 15981 16796 16122 16891 21259>,
			<14546 16046 16576 14325 16998 20212>,
			<15466 16069 16329 13535 17032 19591>,
			<15519 16042 16017 13899 16970 19391>,
			<15541 15968 15681 14624 16808 19269>,
			<15548 15884 15483 14811 16624 19057>,
			<15551 15780 15374 14514 16404 18684>,
			<15552 15636 15290 14126 16107 18209>,
			<15177 15385 15221 13840 15591 17629>,
			<14165 14986 15165 13572 14836 16920>,
			<13764 14555 15035 13311 14240 16204>,
			<14823 13980 14428 13002 13740 15451>,
			<16057 13537 13805 12785 13420 14749>,
			<16179 13795 13667 12816 13452 14130>,
			<16075 14873 13606 13021 13682 13565>,
			<16018 15756 13614 13343 14020 13409>,
			<16218 16294 14751 14237 14879 14150>,
			<16506 16660 16285 15434 15747 15290>,
			<16162 16700 16782 16394 15859 16220>,
			<13899 16664 16965 17323 15853 17130>,
			<11921 16642 17196 17734 15850 17921>,
			<11232 16784 17791 17230 16089 18705>,
			<10779 17015 18432 16486 16440 19278>,
			<10692 17022 18561 16407 16488 19011>,
			<10743 16629 18571 16776 16345 17604>,
			<10787 15970 18574 17038 16151 16683>,
			<10780 14239 18492 16802 15876 16588>,
			<10758 11684 18309 16377 15575 16526>,
			<10766 10937 18146 16333 15529 16302>,
			<11073 11073 17973 16900 15767 15667>,
			<11443 11210 17868 17394 16080 15258>,
			<11567 11235 17994 17432 16336 15773>,
			<11630 11244 18280 17443 16595 16674>,
			<11694 11373 18379 17488 16864 16923>,
			<11790 13730 18375 17783 17202 16937>,
			<11870 16330 18368 18061 17437 16954>,
			<11873 16301 17795 17722 17419 17066>,
			<11827 15147 16220 16608 17301 17328>,
			<11756 13967 15513 15699 17144 17698>,
			<11605 12798 15494 15049 16841 18397>,
			<11439 12189 15497 14814 16709 18642>,
			<11367 12213 15758 15637 17526 18496>,
			<11287 12145 15089 15213 16423 17865>,
			<11242 12008 14673 14888 15725 18607>,
			<11336 11846 14644 14938 15872 19403>,
			<11506 12251 14479 15404 16927 20826>,
			<11446 12332 15100 17235 21808 27507>,
			<11471 11805 15359 19146 23803 28887>,
			<10911 11889 13753 17743 22587 24108>,
			<9824 11466 13631 17219 20299 21290>,
			<9083 10270 12537 16917 18457 19288>,
			<9083 10270 12537 16917 18457 19288>,
			<9083 10270 12537 16917 18457 19288>;
	};

	qcom,pc-temp-y6-lut {
		qcom,lut-col-legend = <(-10) 0 10 25 40 50>;
		qcom,lut-row-legend = <10000 9800 9600 9400 9200 9000>,
			<8800 8600 8400 8200 8000 7800>,
			<7600 7400 7200 7000 6800 6600>,
			<6400 6200 6000 5800 5600 5400>,
			<5200 5000 4800 4600 4400 4200>,
			<4000 3800 3600 3400 3200 3000>,
			<2800 2600 2400 2200 2000 1800>,
			<1600 1400 1200 1000 900 800>,
			<700 600 500 400 300 200>,
			<100 0>;
		qcom,lut-data = <5803 5379 5135 4997 4950 4937>,
			<5840 5391 5140 4992 4948 4937>,
			<5862 5397 5142 4988 4947 4937>,
			<5874 5397 5142 4985 4946 4937>,
			<5879 5394 5139 4983 4945 4937>,
			<5880 5389 5136 4982 4945 4938>,
			<5866 5380 5131 4982 4946 4938>,
			<5838 5368 5124 4983 4947 4939>,
			<5829 5357 5119 4985 4947 4939>,
			<5829 5347 5116 4986 4947 4940>,
			<5830 5340 5114 4987 4948 4941>,
			<5833 5338 5115 4989 4949 4942>,
			<5842 5336 5117 4991 4952 4944>,
			<5851 5336 5119 4993 4954 4945>,
			<5860 5349 5122 4996 4957 4947>,
			<5868 5366 5127 4999 4959 4948>,
			<5850 5374 5137 5004 4962 4950>,
			<5778 5380 5155 5012 4966 4952>,
			<5717 5382 5163 5019 4970 4955>,
			<5691 5351 5158 5027 4979 4962>,
			<5670 5300 5149 5034 4986 4968>,
			<5649 5268 5131 5027 4982 4964>,
			<5624 5242 5095 4998 4961 4949>,
			<5611 5228 5073 4978 4948 4941>,
			<5612 5222 5071 4974 4946 4940>,
			<5614 5219 5069 4972 4945 4939>,
			<5618 5218 5069 4973 4945 4939>,
			<5633 5217 5070 4975 4946 4940>,
			<5652 5216 5072 4978 4948 4940>,
			<5670 5215 5073 4981 4950 4942>,
			<5690 5213 5075 4983 4952 4944>,
			<5713 5213 5077 4987 4955 4946>,
			<5744 5222 5079 4991 4959 4949>,
			<5779 5235 5081 4994 4962 4950>,
			<5817 5247 5082 4994 4960 4948>,
			<5858 5262 5084 4991 4955 4943>,
			<5903 5280 5086 4988 4951 4942>,
			<5955 5308 5089 4980 4949 4941>,
			<6012 5339 5092 4974 4948 4941>,
			<6074 5365 5098 4973 4948 4941>,
			<6140 5389 5105 4974 4947 4941>,
			<6214 5418 5115 4975 4947 4941>,
			<6296 5457 5132 4976 4947 4940>,
			<6396 5507 5153 4978 4946 4940>,
			<6542 5574 5179 4980 4947 4939>,
			<6741 5666 5221 4989 4950 4942>,
			<6862 5717 5235 4994 4952 4944>,
			<6964 5757 5239 4997 4953 4945>,
			<7123 5845 5274 5000 4954 4945>,
			<7342 5942 5309 4995 4950 4942>,
			<7670 6049 5335 4999 4951 4944>,
			<8748 6267 5395 5006 4954 4948>,
			<11531 6658 5526 5022 4960 4953>,
			<19183 8041 5734 5065 4975 4986>,
			<19183 8041 5734 5065 4975 4986>,
			<19183 8041 5734 5065 4975 4986>;
	};

};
